# PIC32MZ1025W104132 register map
Vendor: Microchip
Registers are 32-bit, read-write, no defined reset value unless marked. A register's access mark holds for its fields unless they carry their own. Addresses are absolute, and some are shared; only a register's first bit layout is shown; [hi:lo] are bit positions; {n}, {i} and the like mark numbered series.

## DMAC
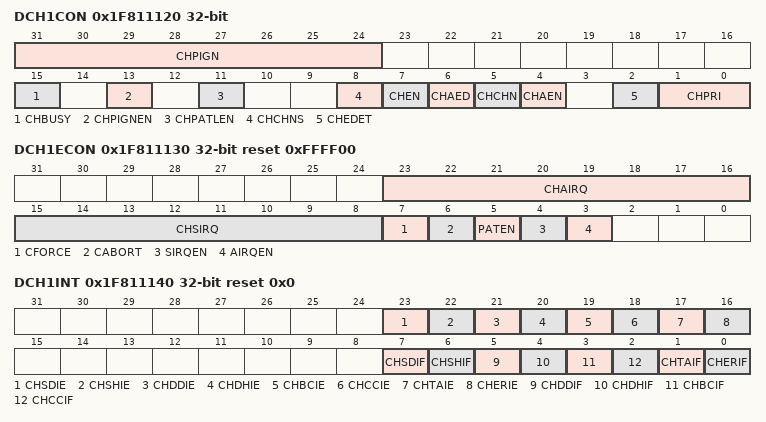
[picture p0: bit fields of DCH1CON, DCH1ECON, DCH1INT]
0x1F811120 DCH1CON — (power-on value xxxxxxxx--------0-0-0--00000-000)
  [31:24] CHPIGN, [15] CHBUSY, [13] CHPIGNEN, [11] CHPATLEN, [8] CHCHNS, [7] CHEN, [6] CHAED, [5] CHCHN, [4] CHAEN, [2] CHEDET ro, [1:0] CHPRI
0x1F811130 DCH1ECON reset 0xFFFF00
  [23:16] CHAIRQ, [15:8] CHSIRQ, [7] CFORCE, [6] CABORT, [5] PATEN, [4] SIRQEN, [3] AIRQEN
0x1F811140 DCH1INT reset 0x0
  [23] CHSDIE, [22] CHSHIE, [21] CHDDIE, [20] CHDHIE, [19] CHBCIE, [18] CHCCIE, [17] CHTAIE, [16] CHERIE, [7] CHSDIF, [6] CHSHIF, [5] CHDDIF, [4] CHDHIF, [3] CHBCIF, [2] CHCCIF, [1] CHTAIF, [0] CHERIF
0x1F811150 DCH1SSA — (power-on value xxxxxxxxxxxxxxxxxxxxxxxxxxxxxxxx)
  [31:0] CHSSA
0x1F811160 DCH1DSA — (power-on value xxxxxxxxxxxxxxxxxxxxxxxxxxxxxxxx)
  [31:0] CHDSA
0x1F811170 DCH1SSIZ — (power-on value ----------------xxxxxxxxxxxxxxxx)
  [15:0] CHSSIZ
0x1F811180 DCH1DSIZ — (power-on value ----------------xxxxxxxxxxxxxxxx)
  [15:0] CHDSIZ
0x1F811190 DCH1SPTR reset 0x0
  [15:0] CHSPTR
0x1F8111A0 DCH1DPTR reset 0x0
  [15:0] CHDPTR
0x1F8111B0 DCH1CSIZ — (power-on value ----------------xxxxxxxxxxxxxxxx)
  [15:0] CHCSIZ
0x1F8111C0 DCH1CPTR reset 0x0
  [15:0] CHCPTR
0x1F8111D0 DCH1DAT — (power-on value ----------------xxxxxxxxxxxxxxxx)
  [15:0] CHPDAT

## icd_jtag_bvci_upb
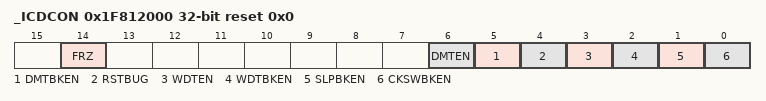
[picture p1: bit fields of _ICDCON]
0x1F812000 _ICDCON reset 0x0
  [14] FRZ, [6] DMTEN, [5] DMTBKEN, [4] RSTBUG, [3] WDTEN, [2] WDTBKEN, [1] SLPBKEN, [0] CKSWBKEN

## _DDPSTAT
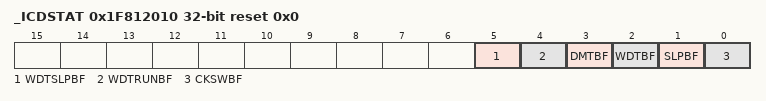
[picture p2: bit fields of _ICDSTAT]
0x1F812010 _ICDSTAT reset 0x0
  [5] WDTSLPBF, [4] WDTRUNBF, [3] DMTBF, [2] WDTBF, [1] SLPBF, [0] CKSWBF

## PCACHE
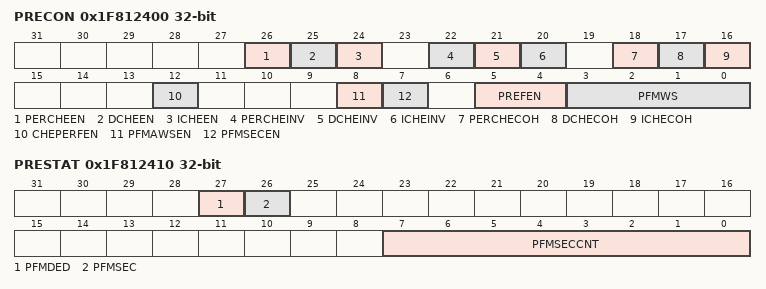
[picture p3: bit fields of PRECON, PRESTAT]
0x1F812400 PRECON — (power-on value -----111-000-000---0---1x-001111)
  [26] PERCHEEN, [25] DCHEEN, [24] ICHEEN, [22] PERCHEINV, [21] DCHEINV, [20] ICHEINV, [18] PERCHECOH, [17] DCHECOH, [16] ICHECOH, [12] CHEPERFEN, [8] PFMAWSEN, [7] PFMSECEN, [5:4] PREFEN, [3:0] PFMWS
0x1F812410 PRESTAT — (power-on value ----xx------------------xxxxxxxx)
  [27] PFMDED, [26] PFMSEC, [7:0] PFMSECCNT
0x1F812420 PREHIT — (power-on value xxxxxxxxxxxxxxxxxxxxxxxxxxxxxxxx)
  [31:0] CHEHIT — (can only be cleared)
0x1F812430 PREMIS — (power-on value xxxxxxxxxxxxxxxxxxxxxxxxxxxxxxxx)
  [31:0] CHEMIS — (can only be cleared)

## gpio_ports_upb
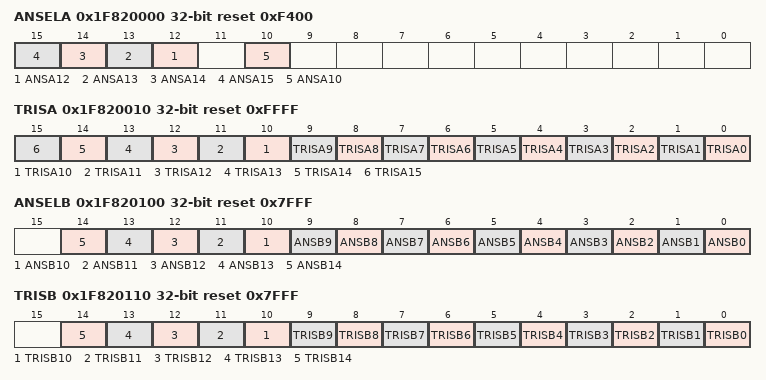
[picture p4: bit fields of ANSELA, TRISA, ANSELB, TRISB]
0x1F820000 ANSELA reset 0xF400
  [n] ANSA{n} (n=12..15), [10] ANSA10
0x1F820010 TRISA reset 0xFFFF
  [n] TRISA{n} (n=0..15)
0x1F820100 ANSELB reset 0x7FFF
  [n] ANSB{n} (n=0..14)
0x1F820110 TRISB reset 0x7FFF
  [n] TRISB{n} (n=0..14)
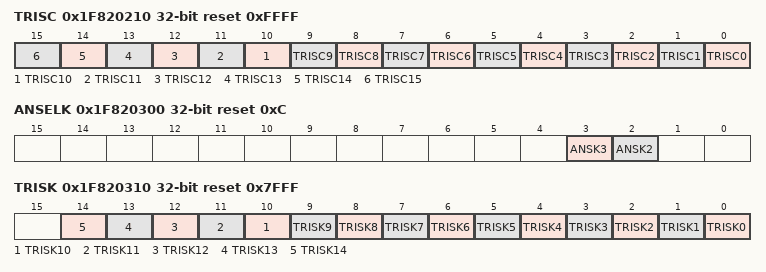
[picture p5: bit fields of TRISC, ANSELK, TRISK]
0x1F820210 TRISC reset 0xFFFF
  [n] TRISC{n} (n=0..15)
0x1F820300 ANSELK reset 0xC
  [3] ANSK3, [2] ANSK2
0x1F820310 TRISK reset 0x7FFF
  [n] TRISK{n} (n=0..14)

## PORTA
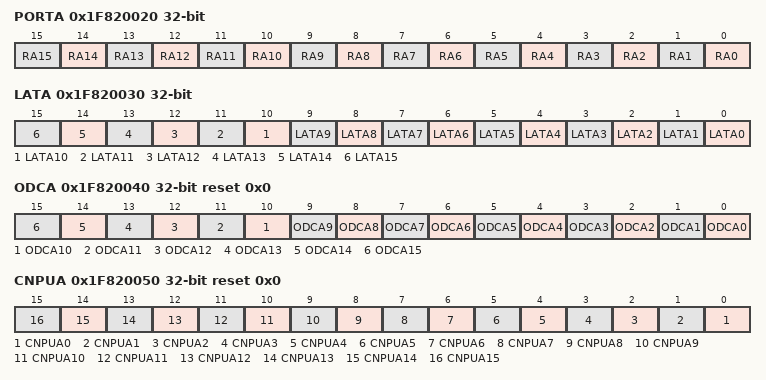
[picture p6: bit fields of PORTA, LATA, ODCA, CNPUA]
0x1F820020 PORTA — (power-on value ----------------xxxxxxxxxxxxxxxx)
  [n] RA{n} (n=0..15)
0x1F820030 LATA — (power-on value ----------------xxxxxxxxxxxxxxxx)
  [n] LATA{n} (n=0..15)
0x1F820040 ODCA reset 0x0
  [n] ODCA{n} (n=0..15)
0x1F820050 CNPUA reset 0x0
  [n] CNPUA{n} (n=0..15)
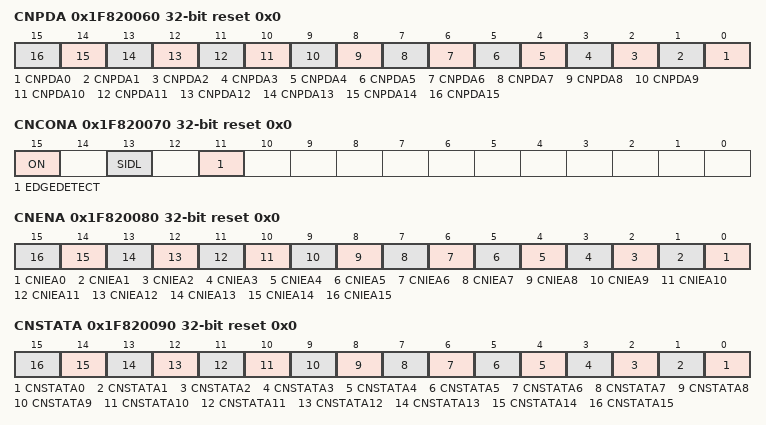
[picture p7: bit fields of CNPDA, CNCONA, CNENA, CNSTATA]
0x1F820060 CNPDA reset 0x0
  [n] CNPDA{n} (n=0..15)
0x1F820070 CNCONA reset 0x0
  [15] ON, [13] SIDL, [11] EDGEDETECT
0x1F820080 CNENA reset 0x0
  [n] CNIEA{n} (n=0..15)
0x1F820090 CNSTATA reset 0x0
  [n] CNSTATA{n} (n=0..15)
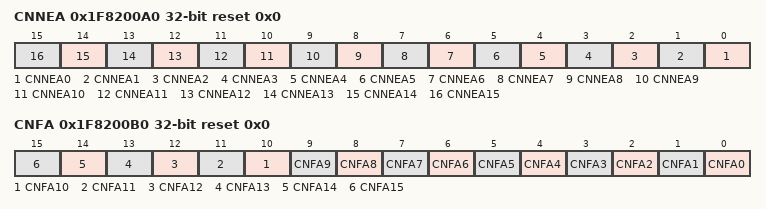
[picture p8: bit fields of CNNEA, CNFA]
0x1F8200A0 CNNEA reset 0x0
  [n] CNNEA{n} (n=0..15)
0x1F8200B0 CNFA reset 0x0
  [n] CNFA{n} (n=0..15)
0x1F8200C0 SRCON0A reset 0x0
  [0] SR0A0
0x1F8200D0 SRCON1A reset 0x0
  [0] SR1A0

## PORTB
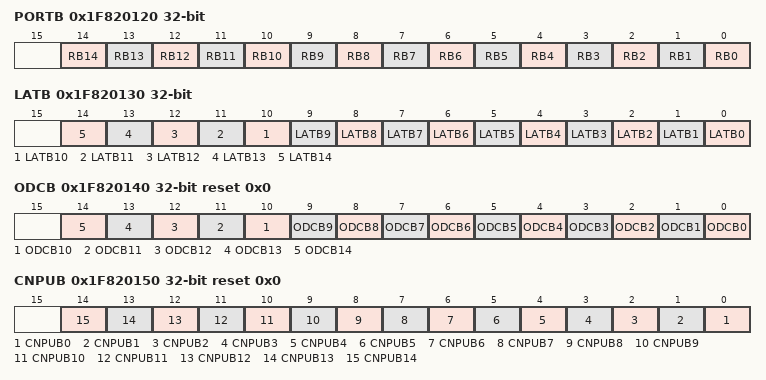
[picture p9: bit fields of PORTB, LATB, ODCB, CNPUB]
0x1F820120 PORTB — (power-on value -----------------xxxxxxxxxxxxxxx)
  [n] RB{n} (n=0..14)
0x1F820130 LATB — (power-on value -----------------xxxxxxxxxxxxxxx)
  [n] LATB{n} (n=0..14)
0x1F820140 ODCB reset 0x0
  [n] ODCB{n} (n=0..14)
0x1F820150 CNPUB reset 0x0
  [n] CNPUB{n} (n=0..14)
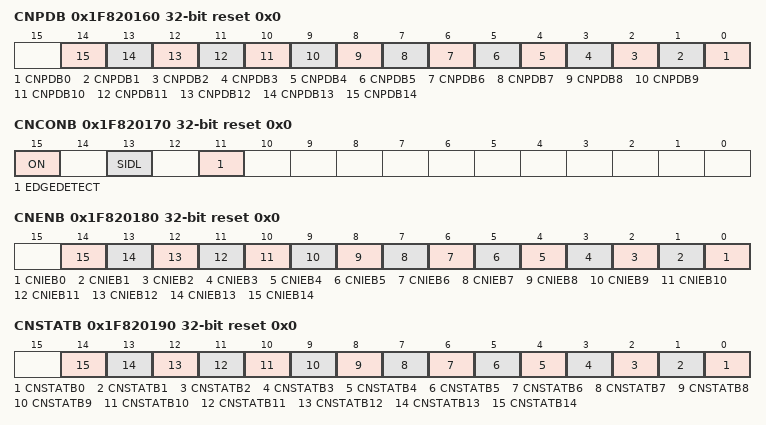
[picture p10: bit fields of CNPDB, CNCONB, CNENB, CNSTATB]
0x1F820160 CNPDB reset 0x0
  [n] CNPDB{n} (n=0..14)
0x1F820170 CNCONB reset 0x0
  [15] ON, [13] SIDL, [11] EDGEDETECT
0x1F820180 CNENB reset 0x0
  [n] CNIEB{n} (n=0..14)
0x1F820190 CNSTATB reset 0x0
  [n] CNSTATB{n} (n=0..14)
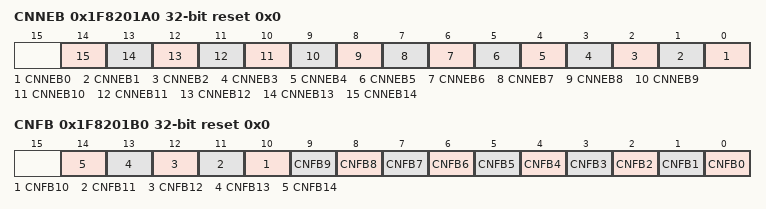
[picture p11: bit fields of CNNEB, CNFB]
0x1F8201A0 CNNEB reset 0x0
  [n] CNNEB{n} (n=0..14)
0x1F8201B0 CNFB reset 0x0
  [n] CNFB{n} (n=0..14)
